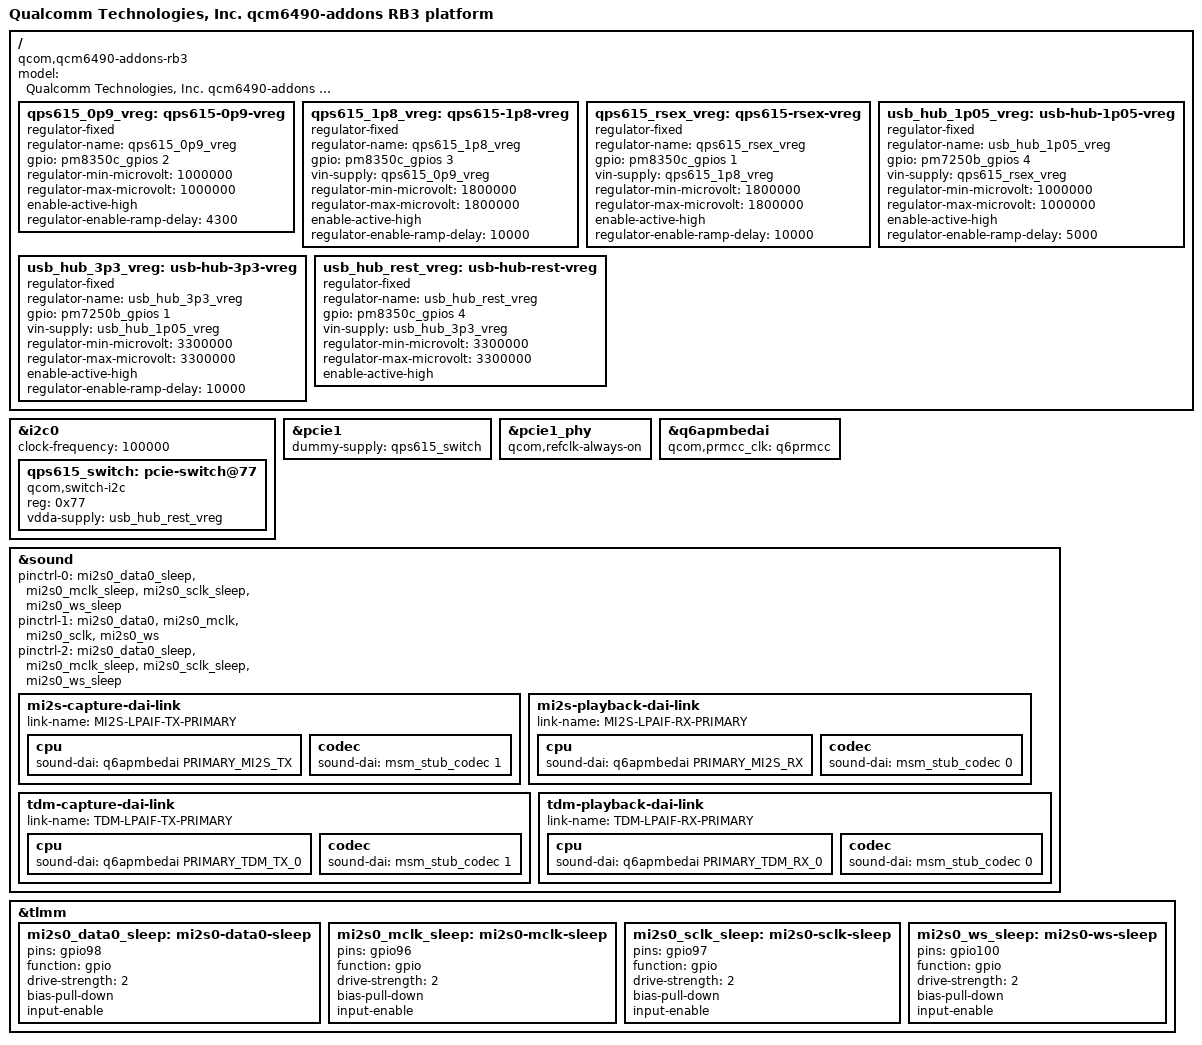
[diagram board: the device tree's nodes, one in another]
// SPDX-License-Identifier: BSD-3-Clause
/*
 * qcm6490-addons RB3 device tree source
 *
 * Copyright (c) 2023 Qualcomm Innovation Center, Inc. All rights reserved.
 *
 */

/dts-v1/;

#include "qcm6490-rb3.dts"
#include "qcm6490-addons.dtsi"

/ {
	model = "Qualcomm Technologies, Inc. qcm6490-addons RB3 platform";
	compatible = "qcom,qcm6490-addons-rb3","qcom,sc7280";

	qps615_0p9_vreg: qps615-0p9-vreg {
		compatible = "regulator-fixed";
		regulator-name = "qps615_0p9_vreg";
		gpio = <&pm8350c_gpios 2 0>;
		regulator-min-microvolt = <1000000>;
		regulator-max-microvolt = <1000000>;
		enable-active-high;
		regulator-enable-ramp-delay = <4300>;
	};

	qps615_1p8_vreg: qps615-1p8-vreg {
		compatible = "regulator-fixed";
		regulator-name = "qps615_1p8_vreg";
		gpio = <&pm8350c_gpios 3 0>;
		vin-supply = <&qps615_0p9_vreg>;
		regulator-min-microvolt = <1800000>;
		regulator-max-microvolt = <1800000>;
		enable-active-high;
		regulator-enable-ramp-delay = <10000>;
	};

	qps615_rsex_vreg: qps615-rsex-vreg {
		compatible = "regulator-fixed";
		regulator-name = "qps615_rsex_vreg";
		gpio = <&pm8350c_gpios 1 0>;
		vin-supply = <&qps615_1p8_vreg>;
		regulator-min-microvolt = <1800000>;
		regulator-max-microvolt = <1800000>;
		enable-active-high;
		regulator-enable-ramp-delay = <10000>;
	};

	usb_hub_1p05_vreg: usb-hub-1p05-vreg {
		compatible = "regulator-fixed";
		regulator-name = "usb_hub_1p05_vreg";
		gpio = <&pm7250b_gpios 4 0>;
		vin-supply = <&qps615_rsex_vreg>;
		regulator-min-microvolt = <1000000>;
		regulator-max-microvolt = <1000000>;
		enable-active-high;
		regulator-enable-ramp-delay = <5000>;
	};

	usb_hub_3p3_vreg: usb-hub-3p3-vreg {
		compatible = "regulator-fixed";
		regulator-name = "usb_hub_3p3_vreg";
		gpio = <&pm7250b_gpios 1 0>;
		vin-supply = <&usb_hub_1p05_vreg>;
		regulator-min-microvolt = <3300000>;
		regulator-max-microvolt = <3300000>;
		enable-active-high;
		regulator-enable-ramp-delay = <10000>;
	};

	usb_hub_rest_vreg: usb-hub-rest-vreg {
		compatible = "regulator-fixed";
		regulator-name = "usb_hub_rest_vreg";
		gpio = <&pm8350c_gpios 4 0>;
		vin-supply = <&usb_hub_3p3_vreg>;
		regulator-min-microvolt = <3300000>;
		regulator-max-microvolt = <3300000>;
		enable-active-high;
	};
};

&i2c0 {
	clock-frequency = <100000>;
	status = "okay";

	qps615_switch: pcie-switch@77 {
		compatible = "qcom,switch-i2c";
		reg = <0x77>;
		vdda-supply = <&usb_hub_rest_vreg>;
		status = "okay";
	};
};

&pcie1 {
	dummy-supply = <&qps615_switch>;
};

&pcie1_phy {
	qcom,refclk-always-on;
};

&q6apmbedai {
	qcom,prmcc_clk = <&q6prmcc>;
};

&sound {

	pinctrl-names = "default", "audio_out_active", "audio_out_sleep";
	pinctrl-0 = <&mi2s0_data0_sleep>, <&mi2s0_mclk_sleep>, <&mi2s0_sclk_sleep>,
		    <&mi2s0_ws_sleep>;
	pinctrl-1 = <&mi2s0_data0>, <&mi2s0_mclk>, <&mi2s0_sclk>, <&mi2s0_ws>;
	pinctrl-2 = <&mi2s0_data0_sleep>, <&mi2s0_mclk_sleep>, <&mi2s0_sclk_sleep>,
		    <&mi2s0_ws_sleep>;

	mi2s-capture-dai-link {
		link-name = "MI2S-LPAIF-TX-PRIMARY";

		cpu {
			sound-dai = <&q6apmbedai PRIMARY_MI2S_TX>;
		};

		codec {
			sound-dai = <&msm_stub_codec 1>;
		};
	};

	mi2s-playback-dai-link {
		link-name = "MI2S-LPAIF-RX-PRIMARY";

		cpu {
			sound-dai = <&q6apmbedai PRIMARY_MI2S_RX>;
		};

		codec {
			sound-dai = <&msm_stub_codec 0>;
		};
	};

	tdm-capture-dai-link {
		link-name = "TDM-LPAIF-TX-PRIMARY";

		cpu {
			sound-dai = <&q6apmbedai PRIMARY_TDM_TX_0>;
		};

		codec {
			sound-dai = <&msm_stub_codec 1>;
		};
	};

	tdm-playback-dai-link {
		link-name = "TDM-LPAIF-RX-PRIMARY";

		cpu {
			sound-dai = <&q6apmbedai PRIMARY_TDM_RX_0>;
		};

		codec {
			sound-dai = <&msm_stub_codec 0>;
		};
	};

};

&tlmm {
	mi2s0_data0_sleep: mi2s0-data0-sleep {
		pins = "gpio98";
		function = "gpio";
		drive-strength = <2>;
		bias-pull-down;
		input-enable;
	};

	mi2s0_mclk_sleep: mi2s0-mclk-sleep {
		pins = "gpio96";
		function = "gpio";
		drive-strength = <2>;
		bias-pull-down;
		input-enable;
	};

	mi2s0_sclk_sleep: mi2s0-sclk-sleep {
		pins = "gpio97";
		function = "gpio";
		drive-strength = <2>;
		bias-pull-down;
		input-enable;
	};

	mi2s0_ws_sleep: mi2s0-ws-sleep {
		pins = "gpio100";
		function = "gpio";
		drive-strength = <2>;
		bias-pull-down;
		input-enable;
	};
};
